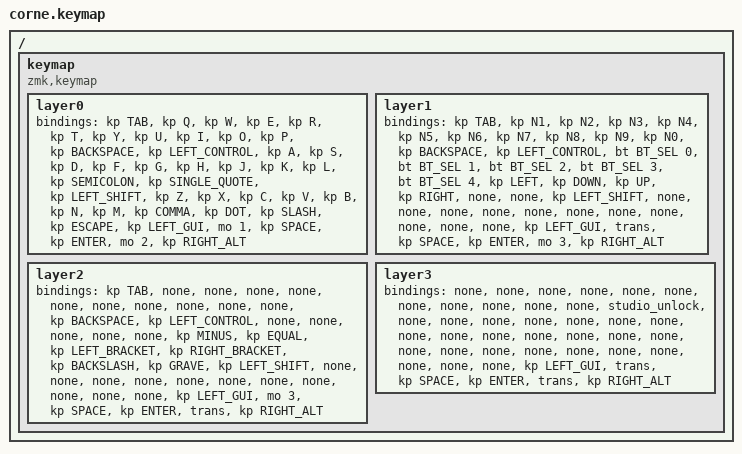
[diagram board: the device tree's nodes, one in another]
  /*
  * Copyright (c) 2020 The ZMK Contributors
  *
  * SPDX-License-Identifier: MIT
  */

  #include <behaviors.dtsi>
  #include <dt-bindings/zmk/keys.h>
  #include <dt-bindings/zmk/bt.h>
  #include <dt-bindings/zmk/ext_power.h>

  / {
    keymap {
      compatible = "zmk,keymap";
  layer0 {
          bindings = <
          &kp TAB &kp Q &kp W &kp E &kp R &kp T &kp Y &kp U &kp I &kp O &kp P &kp BACKSPACE &kp LEFT_CONTROL &kp A &kp S &kp D &kp F &kp G &kp H &kp J &kp K &kp L &kp SEMICOLON &kp SINGLE_QUOTE &kp LEFT_SHIFT &kp Z &kp X &kp C &kp V &kp B &kp N &kp M &kp COMMA &kp DOT &kp SLASH &kp ESCAPE &kp LEFT_GUI &mo 1 &kp SPACE &kp ENTER &mo 2 &kp RIGHT_ALT
          >;
        };layer1 {
          bindings = <
          &kp TAB &kp N1 &kp N2 &kp N3 &kp N4 &kp N5 &kp N6 &kp N7 &kp N8 &kp N9 &kp N0 &kp BACKSPACE &kp LEFT_CONTROL &bt BT_SEL 0 &bt BT_SEL 1 &bt BT_SEL 2 &bt BT_SEL 3 &bt BT_SEL 4 &kp LEFT &kp DOWN &kp UP &kp RIGHT &none &none &kp LEFT_SHIFT &none &none &none &none &none &none &none &none &none &none &none &kp LEFT_GUI &trans &kp SPACE &kp ENTER &mo 3 &kp RIGHT_ALT
          >;
        };layer2 {
          bindings = <
          &kp TAB &none &none &none &none &none &none &none &none &none &none &kp BACKSPACE &kp LEFT_CONTROL &none &none &none &none &none &kp MINUS &kp EQUAL &kp LEFT_BRACKET &kp RIGHT_BRACKET &kp BACKSLASH &kp GRAVE &kp LEFT_SHIFT &none &none &none &none &none &none &none &none &none &none &none &kp LEFT_GUI &mo 3 &kp SPACE &kp ENTER &trans &kp RIGHT_ALT
          >;
        };layer3 {
          bindings = <
          &none &none &none &none &none &none &none &none &none &none &none &studio_unlock &none &none &none &none &none &none &none &none &none &none &none &none &none &none &none &none &none &none &none &none &none &none &none &none &kp LEFT_GUI &trans &kp SPACE &kp ENTER &trans &kp RIGHT_ALT
          >;
        };
    };
  };
  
